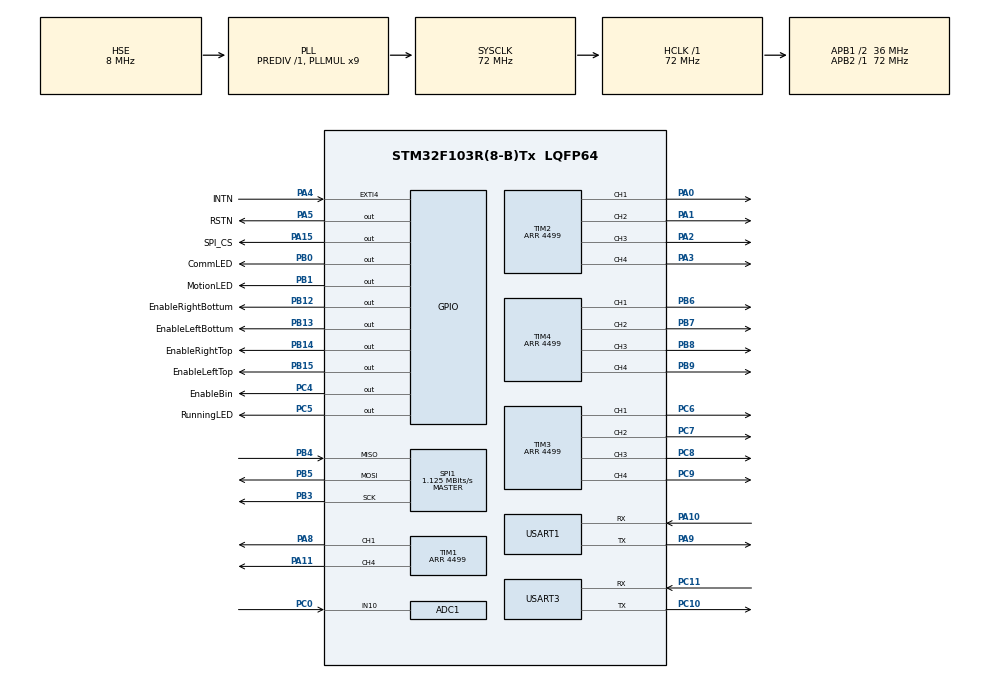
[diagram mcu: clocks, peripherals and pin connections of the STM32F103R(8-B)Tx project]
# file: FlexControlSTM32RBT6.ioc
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ADC1.Channel-0\#ChannelRegularConversion=ADC_CHANNEL_10
ADC1.NbrOfConversionFlag=1
ADC1.Rank-0\#ChannelRegularConversion=1
ADC1.SamplingTime-0\#ChannelRegularConversion=ADC_SAMPLETIME_239CYCLES_5
ADC1.master=1
Dma.Request0=USART1_TX
Dma.Request1=USART1_RX
Dma.Request2=SPI1_TX
Dma.Request3=SPI1_RX
Dma.SPI1_RX.3.Direction=DMA_PERIPH_TO_MEMORY
Dma.SPI1_RX.3.Instance=DMA1_Channel2
Dma.SPI1_RX.3.MemDataAlignment=DMA_MDATAALIGN_BYTE
Dma.SPI1_RX.3.MemInc=DMA_MINC_ENABLE
Dma.SPI1_RX.3.Mode=DMA_NORMAL
Dma.SPI1_RX.3.PeriphDataAlignment=DMA_PDATAALIGN_BYTE
Dma.SPI1_RX.3.PeriphInc=DMA_PINC_DISABLE
Dma.SPI1_RX.3.Priority=DMA_PRIORITY_LOW
Dma.SPI1_TX.2.Direction=DMA_MEMORY_TO_PERIPH
Dma.SPI1_TX.2.Instance=DMA1_Channel3
Dma.SPI1_TX.2.MemDataAlignment=DMA_MDATAALIGN_BYTE
Dma.SPI1_TX.2.MemInc=DMA_MINC_ENABLE
Dma.SPI1_TX.2.Mode=DMA_NORMAL
Dma.SPI1_TX.2.PeriphDataAlignment=DMA_PDATAALIGN_BYTE
Dma.SPI1_TX.2.PeriphInc=DMA_PINC_DISABLE
Dma.SPI1_TX.2.Priority=DMA_PRIORITY_LOW
Dma.USART1_RX.1.Direction=DMA_PERIPH_TO_MEMORY
Dma.USART1_RX.1.Instance=DMA1_Channel5
Dma.USART1_RX.1.MemDataAlignment=DMA_MDATAALIGN_BYTE
Dma.USART1_RX.1.MemInc=DMA_MINC_ENABLE
Dma.USART1_RX.1.Mode=DMA_CIRCULAR
Dma.USART1_RX.1.PeriphDataAlignment=DMA_PDATAALIGN_BYTE
Dma.USART1_RX.1.PeriphInc=DMA_PINC_DISABLE
Dma.USART1_RX.1.Priority=DMA_PRIORITY_LOW
Dma.USART1_TX.0.Direction=DMA_MEMORY_TO_PERIPH
Dma.USART1_TX.0.Instance=DMA1_Channel4
Dma.USART1_TX.0.MemDataAlignment=DMA_MDATAALIGN_BYTE
Dma.USART1_TX.0.MemInc=DMA_MINC_ENABLE
Dma.USART1_TX.0.Mode=DMA_NORMAL
Dma.USART1_TX.0.PeriphDataAlignment=DMA_PDATAALIGN_BYTE
Dma.USART1_TX.0.PeriphInc=DMA_PINC_DISABLE
Dma.USART1_TX.0.Priority=DMA_PRIORITY_LOW
Mcu.Family=STM32F1
Mcu.Name=STM32F103R(8-B)Tx
Mcu.Package=LQFP64
NVIC.ADC1_2_IRQn=true\:0\:0\:false\:false\:true\:true\:true\:true
NVIC.DMA1_Channel2_IRQn=true\:0\:0\:false\:false\:true\:false\:true\:true
NVIC.DMA1_Channel3_IRQn=true\:0\:0\:false\:false\:true\:false\:true\:true
NVIC.DMA1_Channel4_IRQn=true\:0\:0\:false\:false\:true\:false\:true\:true
NVIC.DMA1_Channel5_IRQn=true\:0\:0\:false\:false\:true\:false\:true\:true
NVIC.EXTI4_IRQn=true\:0\:0\:false\:false\:true\:true\:true\:true
NVIC.PriorityGroup=NVIC_PRIORITYGROUP_4
NVIC.SPI1_IRQn=true\:0\:0\:false\:false\:true\:true\:true\:true
NVIC.TIM2_IRQn=true\:0\:0\:false\:false\:true\:true\:true\:true
NVIC.TIM3_IRQn=true\:0\:0\:false\:false\:true\:true\:true\:true
NVIC.TIM4_IRQn=true\:0\:0\:false\:false\:true\:true\:true\:true
NVIC.USART1_IRQn=true\:0\:0\:false\:false\:true\:false\:true\:true
NVIC.USART3_IRQn=true\:0\:0\:false\:false\:true\:false\:true\:true
PA0-WKUP.Signal=S_TIM2_CH1_ETR
PA1.Signal=S_TIM2_CH2
PA10.Mode=Asynchronous
PA10.Signal=USART1_RX
PA11.Signal=S_TIM1_CH4
PA13.Mode=Serial_Wire
PA13.Signal=SYS_JTMS-SWDIO
PA14.Mode=Serial_Wire
PA14.Signal=SYS_JTCK-SWCLK
PA15.GPIO_Label=SPI_CS
PA15.Signal=GPIO_Output
PA2.Signal=S_TIM2_CH3
PA3.Signal=S_TIM2_CH4
PA4.GPIO_Label=INTN
PA4.GPIO_ModeDefaultEXTI=GPIO_MODE_IT_FALLING
PA4.GPIO_PuPd=GPIO_PULLUP
PA4.Signal=GPXTI4
PA5.GPIO_Label=RSTN
PA5.Signal=GPIO_Output
PA8.Signal=S_TIM1_CH1
PA9.Mode=Asynchronous
PA9.Signal=USART1_TX
PB0.GPIO_Label=CommLED
PB0.PinState=GPIO_PIN_SET
PB0.Signal=GPIO_Output
PB1.GPIO_Label=MotionLED
PB1.PinState=GPIO_PIN_SET
PB1.Signal=GPIO_Output
PB12.GPIO_Label=EnableRightBottum
PB12.PinState=GPIO_PIN_SET
PB12.Signal=GPIO_Output
PB13.GPIO_Label=EnableLeftBottum
PB13.PinState=GPIO_PIN_SET
PB13.Signal=GPIO_Output
PB14.GPIO_Label=EnableRightTop
PB14.PinState=GPIO_PIN_SET
PB14.Signal=GPIO_Output
PB15.GPIO_Label=EnableLeftTop
PB15.PinState=GPIO_PIN_SET
PB15.Signal=GPIO_Output
PB3.Mode=Full_Duplex_Master
PB3.Signal=SPI1_SCK
PB4.Mode=Full_Duplex_Master
PB4.Signal=SPI1_MISO
PB5.Mode=Full_Duplex_Master
PB5.Signal=SPI1_MOSI
PB6.Signal=S_TIM4_CH1
PB7.Signal=S_TIM4_CH2
PB8.Signal=S_TIM4_CH3
PB9.Signal=S_TIM4_CH4
PC0.Signal=ADCx_IN10
PC10.Mode=Asynchronous
PC10.Signal=USART3_TX
PC11.Mode=Asynchronous
PC11.Signal=USART3_RX
PC4.GPIO_Label=EnableBin
PC4.PinState=GPIO_PIN_SET
PC4.Signal=GPIO_Output
PC5.GPIO_Label=RunningLED
PC5.PinState=GPIO_PIN_SET
PC5.Signal=GPIO_Output
PC6.Signal=S_TIM3_CH1
PC7.Signal=S_TIM3_CH2
PC8.Signal=S_TIM3_CH3
PC9.Signal=S_TIM3_CH4
PD0-OSC_IN.Mode=HSE-External-Oscillator
PD0-OSC_IN.Signal=RCC_OSC_IN
PD1-OSC_OUT.Mode=HSE-External-Oscillator
PD1-OSC_OUT.Signal=RCC_OSC_OUT
ProjectManager.HeapSize=0x200
ProjectManager.StackSize=0x400
ProjectManager.TargetToolchain=MDK-ARM V5.32
RCC.ADCPresc=RCC_ADCPCLK2_DIV8
RCC.AHBFreq_Value=72000000
RCC.APB1CLKDivider=RCC_HCLK_DIV2
RCC.APB1Freq_Value=36000000
RCC.APB1TimFreq_Value=72000000
RCC.APB2Freq_Value=72000000
RCC.APB2TimFreq_Value=72000000
RCC.HCLKFreq_Value=72000000
RCC.PLLMUL=RCC_PLL_MUL9
RCC.PLLSourceVirtual=RCC_PLLSOURCE_HSE
RCC.SYSCLKFreq_VALUE=72000000
RCC.SYSCLKSource=RCC_SYSCLKSOURCE_PLLCLK
RCC.USBFreq_Value=72000000
SH.ADCx_IN10.0=ADC1_IN10,IN10
SH.S_TIM1_CH1.0=TIM1_CH1,PWM Generation1 CH1
SH.S_TIM1_CH4.0=TIM1_CH4,PWM Generation4 CH4
SH.S_TIM2_CH1_ETR.0=TIM2_CH1,PWM Generation1 CH1
SH.S_TIM2_CH2.0=TIM2_CH2,PWM Generation2 CH2
SH.S_TIM2_CH3.0=TIM2_CH3,PWM Generation3 CH3
SH.S_TIM2_CH4.0=TIM2_CH4,PWM Generation4 CH4
SH.S_TIM3_CH1.0=TIM3_CH1,PWM Generation1 CH1
SH.S_TIM3_CH2.0=TIM3_CH2,PWM Generation2 CH2
SH.S_TIM3_CH3.0=TIM3_CH3,PWM Generation3 CH3
SH.S_TIM3_CH4.0=TIM3_CH4,PWM Generation4 CH4
SH.S_TIM4_CH1.0=TIM4_CH1,PWM Generation1 CH1
SH.S_TIM4_CH2.0=TIM4_CH2,PWM Generation2 CH2
SH.S_TIM4_CH3.0=TIM4_CH3,PWM Generation3 CH3
SH.S_TIM4_CH4.0=TIM4_CH4,PWM Generation4 CH4
SPI1.BaudRatePrescaler=SPI_BAUDRATEPRESCALER_64
SPI1.CalculateBaudRate=1.125 MBits/s
SPI1.Direction=SPI_DIRECTION_2LINES
SPI1.Mode=SPI_MODE_MASTER
SPI1.VirtualType=VM_MASTER
TIM1.Channel-PWM\ Generation1\ CH1=TIM_CHANNEL_1
TIM1.Channel-PWM\ Generation4\ CH4=TIM_CHANNEL_4
TIM1.Period=4499
TIM2.Channel-PWM\ Generation1\ CH1=TIM_CHANNEL_1
TIM2.Channel-PWM\ Generation2\ CH2=TIM_CHANNEL_2
TIM2.Channel-PWM\ Generation3\ CH3=TIM_CHANNEL_3
TIM2.Channel-PWM\ Generation4\ CH4=TIM_CHANNEL_4
TIM2.Period=4499
TIM3.Channel-PWM\ Generation1\ CH1=TIM_CHANNEL_1
TIM3.Channel-PWM\ Generation2\ CH2=TIM_CHANNEL_2
TIM3.Channel-PWM\ Generation3\ CH3=TIM_CHANNEL_3
TIM3.Channel-PWM\ Generation4\ CH4=TIM_CHANNEL_4
TIM3.Period=4499
TIM4.Channel-PWM\ Generation1\ CH1=TIM_CHANNEL_1
TIM4.Channel-PWM\ Generation2\ CH2=TIM_CHANNEL_2
TIM4.Channel-PWM\ Generation3\ CH3=TIM_CHANNEL_3
TIM4.Channel-PWM\ Generation4\ CH4=TIM_CHANNEL_4
TIM4.Period=4499
USART1.VirtualMode=VM_ASYNC
USART3.VirtualMode=VM_ASYNC
board=custom

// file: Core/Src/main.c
/* USER CODE BEGIN Header */
/**
  ******************************************************************************
  * @file           : main.c
  * @brief          : Main program body
  ******************************************************************************
  * @attention
  *
  * Copyright (c) 2026 STMicroelectronics.
  * All rights reserved.
  *
  * This software is licensed under terms that can be found in the LICENSE file
  * in the root directory of this software component.
  * If no LICENSE file comes with this software, it is provided AS-IS.
  *
  ******************************************************************************
  */
/* USER CODE END Header */
#include "main.h"
#include "adc.h"
#include "dma.h"
#include "spi.h"
#include "tim.h"
#include "usart.h"
#include "gpio.h"

/* USER CODE BEGIN Includes */
#include "FlexControl.h"
/* USER CODE END Includes */

void SystemClock_Config(void);

int main(void)
{

  /* MCU Configuration--------------------------------------------------------*/

  /* Reset of all peripherals, Initializes the Flash interface and the Systick. */
  HAL_Init();

  /* Configure the system clock */
  SystemClock_Config();

  /* Initialize all configured peripherals */
  MX_GPIO_Init();
  MX_DMA_Init();
  MX_USART1_UART_Init();
  MX_ADC1_Init();
  MX_SPI1_Init();
  MX_TIM1_Init();
  MX_TIM2_Init();
  MX_TIM3_Init();
  MX_TIM4_Init();
  MX_USART3_UART_Init();
  /* USER CODE BEGIN 2 */
  HAL_GPIO_WritePin(RSTN_GPIO_Port, RSTN_Pin, GPIO_PIN_SET);
  HAL_GPIO_WritePin(SPI_CS_GPIO_Port, SPI_CS_Pin, GPIO_PIN_SET);

  FlexControlInit();
  /* USER CODE END 2 */

  /* Infinite loop */
  while (1)
  {

    /* USER CODE BEGIN 3 */
	FlexControlHandle();
  }
  /* USER CODE END 3 */
}

void SystemClock_Config(void)
{
  RCC_OscInitTypeDef RCC_OscInitStruct = {0};
  RCC_ClkInitTypeDef RCC_ClkInitStruct = {0};
  RCC_PeriphCLKInitTypeDef PeriphClkInit = {0};

  /** Initializes the RCC Oscillators according to the specified parameters
  * in the RCC_OscInitTypeDef structure.
  */
  RCC_OscInitStruct.OscillatorType = RCC_OSCILLATORTYPE_HSE;
  RCC_OscInitStruct.HSEState = RCC_HSE_ON;
  RCC_OscInitStruct.HSEPredivValue = RCC_HSE_PREDIV_DIV1;
  RCC_OscInitStruct.HSIState = RCC_HSI_ON;
  RCC_OscInitStruct.PLL.PLLState = RCC_PLL_ON;
  RCC_OscInitStruct.PLL.PLLSource = RCC_PLLSOURCE_HSE;
  RCC_OscInitStruct.PLL.PLLMUL = RCC_PLL_MUL9;
  if (HAL_RCC_OscConfig(&RCC_OscInitStruct) != HAL_OK)
  {
    Error_Handler();
  }

  /** Initializes the CPU, AHB and APB buses clocks
  */
  RCC_ClkInitStruct.ClockType = RCC_CLOCKTYPE_HCLK|RCC_CLOCKTYPE_SYSCLK
                              |RCC_CLOCKTYPE_PCLK1|RCC_CLOCKTYPE_PCLK2;
  RCC_ClkInitStruct.SYSCLKSource = RCC_SYSCLKSOURCE_PLLCLK;
  RCC_ClkInitStruct.AHBCLKDivider = RCC_SYSCLK_DIV1;
  RCC_ClkInitStruct.APB1CLKDivider = RCC_HCLK_DIV2;
  RCC_ClkInitStruct.APB2CLKDivider = RCC_HCLK_DIV1;

  if (HAL_RCC_ClockConfig(&RCC_ClkInitStruct, FLASH_LATENCY_2) != HAL_OK)
  {
    Error_Handler();
  }
  PeriphClkInit.PeriphClockSelection = RCC_PERIPHCLK_ADC;
  PeriphClkInit.AdcClockSelection = RCC_ADCPCLK2_DIV8;
  if (HAL_RCCEx_PeriphCLKConfig(&PeriphClkInit) != HAL_OK)
  {
    Error_Handler();
  }
}

void Error_Handler(void)
{
  __disable_irq();
  while (1)
  {
  }
}
